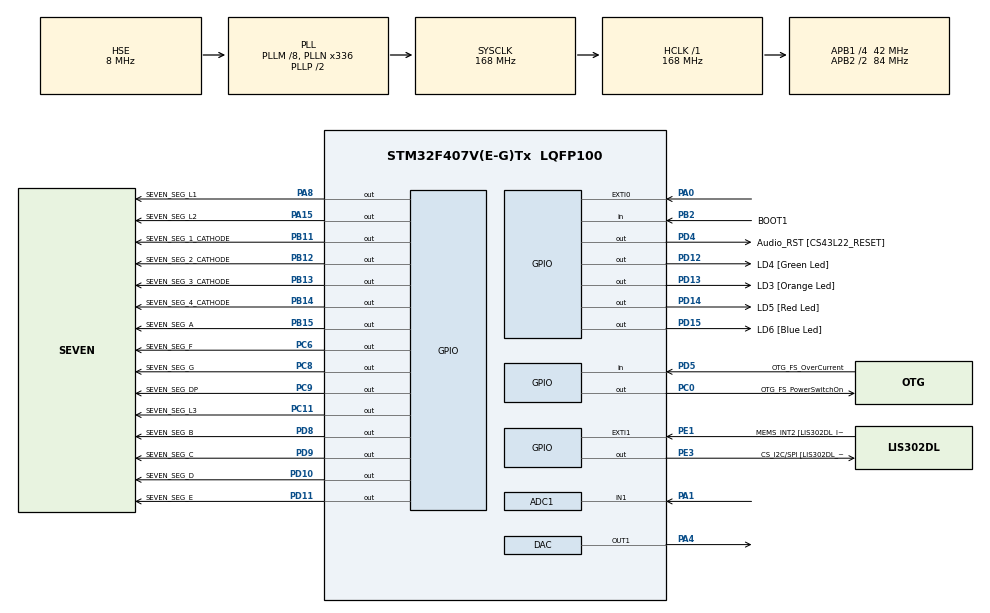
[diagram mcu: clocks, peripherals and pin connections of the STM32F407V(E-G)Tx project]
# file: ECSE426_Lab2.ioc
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ADC1.Channel-0\#ChannelRegularConversion=ADC_CHANNEL_1
ADC1.ClockPrescaler=ADC_CLOCK_SYNC_PCLK_DIV4
ADC1.ContinuousConvMode=DISABLE
ADC1.DMAContinuousRequests=DISABLE
ADC1.DataAlign=ADC_DATAALIGN_RIGHT
ADC1.DiscontinuousConvMode=DISABLE
ADC1.EOCSelection=ADC_EOC_SINGLE_CONV
ADC1.EnableAnalogWatchDog=false
ADC1.ExternalTrigConv=ADC_SOFTWARE_START
ADC1.ExternalTrigConvEdge=ADC_EXTERNALTRIGCONVEDGE_NONE
ADC1.InjNumberOfConversion=0
ADC1.NbrOfConversion=1
ADC1.NbrOfConversionFlag=1
ADC1.Rank-0\#ChannelRegularConversion=1
ADC1.Resolution=ADC_RESOLUTION_10B
ADC1.SamplingTime-0\#ChannelRegularConversion=ADC_SAMPLETIME_3CYCLES
ADC1.ScanConvMode=DISABLE
ADC1.master=1
Mcu.Family=STM32F4
Mcu.Name=STM32F407V(E-G)Tx
Mcu.Package=LQFP100
NVIC.ADC_IRQn=true\:0\:0\:false\:true\:true\:1\:true
NVIC.PriorityGroup=NVIC_PRIORITYGROUP_0
PA0-WKUP.Signal=GPXTI0
PA1.Signal=ADCx_IN1
PA10.GPIO_Label=OTG_FS_ID
PA10.GPIO_Mode=GPIO_MODE_AF_PP
PA10.GPIO_PuPd=GPIO_NOPULL
PA10.GPIO_Speed=GPIO_SPEED_FREQ_LOW
PA10.Signal=USB_OTG_FS_ID
PA11.GPIO_Label=OTG_FS_DM
PA11.GPIO_Mode=GPIO_MODE_AF_PP
PA11.GPIO_PuPd=GPIO_NOPULL
PA11.GPIO_Speed=GPIO_SPEED_FREQ_LOW
PA11.Signal=USB_OTG_FS_DM
PA12.GPIO_Label=OTG_FS_DP
PA12.GPIO_Mode=GPIO_MODE_AF_PP
PA12.GPIO_PuPd=GPIO_NOPULL
PA12.GPIO_Speed=GPIO_SPEED_FREQ_LOW
PA12.Signal=USB_OTG_FS_DP
PA13.GPIO_Label=SWDIO
PA13.Mode=Serial_Wire
PA13.Signal=SYS_JTMS-SWDIO
PA14.GPIO_Label=SWCLK
PA14.Mode=Serial_Wire
PA14.Signal=SYS_JTCK-SWCLK
PA15.GPIO_Label=SEVEN_SEG_L2
PA15.Signal=GPIO_Output
PA4.Signal=COMP_DAC1_group
PA5.GPIO_Label=SPI1_SCK [LIS302DL_SCL/SPC]
PA5.GPIO_Mode=GPIO_MODE_AF_PP
PA5.GPIO_PuPd=GPIO_NOPULL
PA5.GPIO_Speed=GPIO_SPEED_FREQ_LOW
PA5.Signal=SPI1_SCK
PA6.GPIO_Label=SPI1_MISO [LIS302DL_SDO]
PA6.GPIO_Mode=GPIO_MODE_AF_PP
PA6.GPIO_PuPd=GPIO_NOPULL
PA6.GPIO_Speed=GPIO_SPEED_FREQ_LOW
PA6.Signal=SPI1_MISO
PA7.GPIO_Label=SPI1_MOSI [LIS302DL_SDA/SDI/SDO]
PA7.GPIO_Mode=GPIO_MODE_AF_PP
PA7.GPIO_PuPd=GPIO_NOPULL
PA7.GPIO_Speed=GPIO_SPEED_FREQ_LOW
PA7.Signal=SPI1_MOSI
PA8.GPIO_Label=SEVEN_SEG_L1
PA8.Signal=GPIO_Output
PA9.GPIO_Label=VBUS_FS
PA9.GPIO_Mode=GPIO_MODE_INPUT
PA9.GPIO_PuPd=GPIO_NOPULL
PA9.Signal=USB_OTG_FS_VBUS
PB10.GPIO_Label=CLK_IN [MP45DT02_CLK]
PB10.GPIO_Mode=GPIO_MODE_AF_PP
PB10.GPIO_PuPd=GPIO_NOPULL
PB10.GPIO_Speed=GPIO_SPEED_FREQ_LOW
PB10.Signal=I2S2_CK
PB11.GPIO_Label=SEVEN_SEG_1_CATHODE 
PB11.Signal=GPIO_Output
PB12.GPIO_Label=SEVEN_SEG_2_CATHODE
PB12.Signal=GPIO_Output
PB13.GPIO_Label=SEVEN_SEG_3_CATHODE
PB13.Signal=GPIO_Output
PB14.GPIO_Label=SEVEN_SEG_4_CATHODE
PB14.Signal=GPIO_Output
PB15.GPIO_Label=SEVEN_SEG_A
PB15.Signal=GPIO_Output
PB2.GPIO_Label=BOOT1
PB2.GPIO_Mode=GPIO_MODE_INPUT
PB2.GPIO_PuPd=GPIO_NOPULL
PB2.Signal=GPIO_Input
PB3.GPIO_Label=SWO
PB3.Signal=SYS_JTDO-SWO
PB6.GPIO_Label=Audio_SCL [CS43L22_SCL]
PB6.GPIO_Mode=GPIO_MODE_AF_OD
PB6.GPIO_PuPd=GPIO_NOPULL
PB6.GPIO_Speed=GPIO_SPEED_FREQ_LOW
PB6.Signal=I2C1_SCL
PB9.GPIO_Label=Audio_SDA [CS43L22_SDA]
PB9.GPIO_Mode=GPIO_MODE_AF_OD
PB9.GPIO_PuPd=GPIO_NOPULL
PB9.GPIO_Speed=GPIO_SPEED_FREQ_LOW
PB9.Signal=I2C1_SDA
PC0.GPIO_Label=OTG_FS_PowerSwitchOn
PC0.GPIO_PuPd=GPIO_NOPULL
PC0.GPIO_Speed=GPIO_SPEED_FREQ_LOW
PC0.PinState=GPIO_PIN_SET
PC0.Signal=GPIO_Output
PC10.GPIO_Label=I2S3_SCK [CS43L22_SCLK]
PC10.GPIO_Mode=GPIO_MODE_AF_PP
PC10.GPIO_PuPd=GPIO_NOPULL
PC10.GPIO_Speed=GPIO_SPEED_FREQ_LOW
PC10.Signal=I2S3_CK
PC11.GPIO_Label=SEVEN_SEG_L3
PC11.Signal=GPIO_Output
PC12.GPIO_Label=I2S3_SD [CS43L22_SDIN]
PC12.GPIO_Mode=GPIO_MODE_AF_PP
PC12.GPIO_PuPd=GPIO_NOPULL
PC12.GPIO_Speed=GPIO_SPEED_FREQ_LOW
PC12.Signal=I2S3_SD
PC14-OSC32_IN.GPIO_Label=PC14-OSC32_IN
PC14-OSC32_IN.Signal=RCC_OSC32_IN
PC15-OSC32_OUT.GPIO_Label=PC15-OSC32_OUT
PC15-OSC32_OUT.Signal=RCC_OSC32_OUT
PC3.GPIO_Label=PDM_OUT [MP45DT02_DOUT]
PC3.GPIO_Mode=GPIO_MODE_AF_PP
PC3.GPIO_PuPd=GPIO_NOPULL
PC3.GPIO_Speed=GPIO_SPEED_FREQ_LOW
PC3.Signal=I2S2_SD
PC6.GPIO_Label=SEVEN_SEG_F
PC6.Signal=GPIO_Output
PC7.GPIO_Label=I2S3_MCK [CS43L22_MCLK]
PC7.GPIO_Mode=GPIO_MODE_AF_PP
PC7.GPIO_PuPd=GPIO_NOPULL
PC7.GPIO_Speed=GPIO_SPEED_FREQ_LOW
PC7.Signal=I2S3_MCK
PC8.GPIO_Label=SEVEN_SEG_G
PC8.Signal=GPIO_Output
PC9.GPIO_Label=SEVEN_SEG_DP
PC9.Signal=GPIO_Output
PD10.GPIO_Label=SEVEN_SEG_D
PD10.Signal=GPIO_Output
PD11.GPIO_Label=SEVEN_SEG_E
PD11.Signal=GPIO_Output
PD12.GPIO_Label=LD4 [Green Led]
PD12.GPIO_PuPd=GPIO_NOPULL
PD12.GPIO_Speed=GPIO_SPEED_FREQ_LOW
PD12.Signal=GPIO_Output
PD13.GPIO_Label=LD3 [Orange Led]
PD13.GPIO_PuPd=GPIO_NOPULL
PD13.GPIO_Speed=GPIO_SPEED_FREQ_LOW
PD13.Signal=GPIO_Output
PD14.GPIO_Label=LD5 [Red Led]
PD14.GPIO_PuPd=GPIO_NOPULL
PD14.GPIO_Speed=GPIO_SPEED_FREQ_LOW
PD14.Signal=GPIO_Output
PD15.GPIO_Label=LD6 [Blue Led]
PD15.GPIO_PuPd=GPIO_NOPULL
PD15.GPIO_Speed=GPIO_SPEED_FREQ_LOW
PD15.Signal=GPIO_Output
PD4.GPIO_Label=Audio_RST [CS43L22_RESET]
PD4.GPIO_PuPd=GPIO_NOPULL
PD4.GPIO_Speed=GPIO_SPEED_FREQ_LOW
PD4.Signal=GPIO_Output
PD5.GPIO_Label=OTG_FS_OverCurrent
PD5.GPIO_Mode=GPIO_MODE_INPUT
PD5.GPIO_PuPd=GPIO_NOPULL
PD5.Signal=GPIO_Input
PD8.GPIO_Label=SEVEN_SEG_B
PD8.Signal=GPIO_Output
PD9.GPIO_Label=SEVEN_SEG_C
PD9.Signal=GPIO_Output
PE1.GPIO_Label=MEMS_INT2 [LIS302DL_INT2]
PE1.GPIO_ModeDefaultEXTI=GPIO_MODE_EVT_RISING
PE1.GPIO_PuPd=GPIO_NOPULL
PE1.Signal=GPXTI1
PE3.GPIO_Label=CS_I2C/SPI [LIS302DL_CS_I2C/SPI]
PE3.GPIO_PuPd=GPIO_NOPULL
PE3.GPIO_Speed=GPIO_SPEED_FREQ_LOW
PE3.Signal=GPIO_Output
PH0-OSC_IN.GPIO_Label=PH0-OSC_IN
PH0-OSC_IN.Mode=HSE-External-Oscillator
PH0-OSC_IN.Signal=RCC_OSC_IN
PH1-OSC_OUT.GPIO_Label=PH1-OSC_OUT
PH1-OSC_OUT.Mode=HSE-External-Oscillator
PH1-OSC_OUT.Signal=RCC_OSC_OUT
ProjectManager.HeapSize=0x200
ProjectManager.StackSize=0x400
ProjectManager.TargetToolchain=MDK-ARM V5
RCC.48MHZClocksFreq_Value=48000000
RCC.AHBFreq_Value=168000000
RCC.APB1CLKDivider=RCC_HCLK_DIV4
RCC.APB1Freq_Value=42000000
RCC.APB1TimFreq_Value=84000000
RCC.APB2CLKDivider=RCC_HCLK_DIV2
RCC.APB2Freq_Value=84000000
RCC.APB2TimFreq_Value=168000000
RCC.CortexFreq_Value=168000000
RCC.HCLKFreq_Value=168000000
RCC.HSE_VALUE=8000000
RCC.HSI_VALUE=16000000
RCC.LSE_VALUE=32768
RCC.PLLM=8
RCC.PLLN=336
RCC.PLLQ=7
RCC.PLLSourceVirtual=RCC_PLLSOURCE_HSE
RCC.SYSCLKFreq_VALUE=168000000
RCC.SYSCLKSource=RCC_SYSCLKSOURCE_PLLCLK
RCC.VCOOutputFreq_Value=336000000
SH.ADCx_IN1.0=ADC1_IN1,IN1
SH.COMP_DAC1_group.0=DAC_OUT1,DAC_OUT1
board=STM32F4DISCOVERY

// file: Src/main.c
/**
  ******************************************************************************
  * @file           : main.c
  * @brief          : Main program body
  ******************************************************************************
  ** This notice applies to any and all portions of this file
  * that are not between comment pairs USER CODE BEGIN and
  * USER CODE END. Other portions of this file, whether
  * inserted by the user or by software development tools
  * are owned by their respective copyright owners.
  *
  * COPYRIGHT(c) 2018 STMicroelectronics
  *
  * Redistribution and use in source and binary forms, with or without modification,
  * are permitted provided that the following conditions are met:
  *   1. Redistributions of source code must retain the above copyright notice,
  *      this list of conditions and the following disclaimer.
  *   2. Redistributions in binary form must reproduce the above copyright notice,
  *      this list of conditions and the following disclaimer in the documentation
  *      and/or other materials provided with the distribution.
  *   3. Neither the name of STMicroelectronics nor the names of its contributors
  *      may be used to endorse or promote products derived from this software
  *      without specific prior written permission.
  *
  * THIS SOFTWARE IS PROVIDED BY THE COPYRIGHT HOLDERS AND CONTRIBUTORS "AS IS"
  * AND ANY EXPRESS OR IMPLIED WARRANTIES, INCLUDING, BUT NOT LIMITED TO, THE
  * IMPLIED WARRANTIES OF MERCHANTABILITY AND FITNESS FOR A PARTICULAR PURPOSE ARE
  * DISCLAIMED. IN NO EVENT SHALL THE COPYRIGHT HOLDER OR CONTRIBUTORS BE LIABLE
  * FOR ANY DIRECT, INDIRECT, INCIDENTAL, SPECIAL, EXEMPLARY, OR CONSEQUENTIAL
  * DAMAGES (INCLUDING, BUT NOT LIMITED TO, PROCUREMENT OF SUBSTITUTE GOODS OR
  * SERVICES; LOSS OF USE, DATA, OR PROFITS; OR BUSINESS INTERRUPTION) HOWEVER
  * CAUSED AND ON ANY THEORY OF LIABILITY, WHETHER IN CONTRACT, STRICT LIABILITY,
  * OR TORT (INCLUDING NEGLIGENCE OR OTHERWISE) ARISING IN ANY WAY OUT OF THE USE
  * OF THIS SOFTWARE, EVEN IF ADVISED OF THE POSSIBILITY OF SUCH DAMAGE.
  *
  ******************************************************************************
  */
#include "main.h"
#include "stm32f4xx_hal.h"
#include "math.h"

ADC_HandleTypeDef hadc1;

DAC_HandleTypeDef hdac;

/* USER CODE BEGIN PV */
/* Private variables ---------------------------------------------------------*/

int input_vector[INPUT_LENGTH] = {0};
float filterOutputVector[INPUT_LENGTH-ORDER] = {0};
int filterOutputLength = INPUT_LENGTH - ORDER;
uint32_t adcConversion;
float filterOutput;
int digits[3] = {0};
float outputVector[3] = {0};
int outputDigits[4] = {0};
int x[5] = {0};

int ledPosition = 0;
int mathCounter = 0;

float rms_value = 0;
float max_value = 0;
float min_value = 0;

volatile int adcTrigger = 0; //triggers the callback conversion
volatile int displaySwitchTrigger = 0; //triggers the switch between LEDs
volatile int displayedValue = 0; //triggers the change between displayed values (RMS, MAX, MIN)
volatile int buttonReadTrigger = 0; //trigger sent from button press

/* USER CODE END PV */

void SystemClock_Config(void);
static void MX_GPIO_Init(void);
static void MX_ADC1_Init(void);
static void MX_DAC_Init(void);
static void MX_NVIC_Init(void);
void HAL_ADC_ConvCpltCallback(ADC_HandleTypeDef* hadc);
void FIR_C(uint32_t input, float *output);
void digitCalc(float* output, int value);
void ledDriver(int ledPos, int number);
void c_math(float input, float outputVector[]);
extern int buttonPressed(void);

/* USER CODE BEGIN PFP */
/* Private function prototypes -----------------------------------------------*/

/* USER CODE END PFP */

int main(void){
  HAL_Init();

  SystemClock_Config();

  MX_GPIO_Init();
  MX_ADC1_Init();
  MX_DAC_Init();
  MX_NVIC_Init();

	HAL_DAC_Start(&hdac, DAC_CHANNEL_1);
	HAL_DAC_SetValue(&hdac, DAC_CHANNEL_1, DAC_ALIGN_12B_R, 000);

  while (1)
  {
		//ADC interrupt every 50 Hz
		if(adcTrigger >= ADC_TIMER){
			adcTrigger = 0;
			HAL_ADC_Start_IT(&hadc1);
		}

		//update LED display at high frequency
		if(displaySwitchTrigger >= LED_POSITION_TIMER){
			displaySwitchTrigger = 0;
			ledPosition++;
			//reset to 0 when ledPosition reaches 4
			ledPosition = ledPosition % 4;
			//at ledPosition x, display outputDigit[x]
			ledDriver(ledPosition, outputDigits[ledPosition]);
		}
	}
}

void SystemClock_Config(void)
{

  RCC_OscInitTypeDef RCC_OscInitStruct;
  RCC_ClkInitTypeDef RCC_ClkInitStruct;

    /**Configure the main internal regulator output voltage
    */
  __HAL_RCC_PWR_CLK_ENABLE();

  __HAL_PWR_VOLTAGESCALING_CONFIG(PWR_REGULATOR_VOLTAGE_SCALE1);

    /**Initializes the CPU, AHB and APB busses clocks
    */
  RCC_OscInitStruct.OscillatorType = RCC_OSCILLATORTYPE_HSE;
  RCC_OscInitStruct.HSEState = RCC_HSE_ON;
  RCC_OscInitStruct.PLL.PLLState = RCC_PLL_ON;
  RCC_OscInitStruct.PLL.PLLSource = RCC_PLLSOURCE_HSE;
  RCC_OscInitStruct.PLL.PLLM = 8;
  RCC_OscInitStruct.PLL.PLLN = 336;
  RCC_OscInitStruct.PLL.PLLP = RCC_PLLP_DIV2;
  RCC_OscInitStruct.PLL.PLLQ = 7;
  if (HAL_RCC_OscConfig(&RCC_OscInitStruct) != HAL_OK)
  {
    _Error_Handler(__FILE__, __LINE__);
  }

    /**Initializes the CPU, AHB and APB busses clocks
    */
  RCC_ClkInitStruct.ClockType = RCC_CLOCKTYPE_HCLK|RCC_CLOCKTYPE_SYSCLK
                              |RCC_CLOCKTYPE_PCLK1|RCC_CLOCKTYPE_PCLK2;
  RCC_ClkInitStruct.SYSCLKSource = RCC_SYSCLKSOURCE_PLLCLK;
  RCC_ClkInitStruct.AHBCLKDivider = RCC_SYSCLK_DIV1;
  RCC_ClkInitStruct.APB1CLKDivider = RCC_HCLK_DIV4;
  RCC_ClkInitStruct.APB2CLKDivider = RCC_HCLK_DIV2;

  if (HAL_RCC_ClockConfig(&RCC_ClkInitStruct, FLASH_LATENCY_5) != HAL_OK)
  {
    _Error_Handler(__FILE__, __LINE__);
  }

    /**Configure the Systick interrupt time
    */
  HAL_SYSTICK_Config(HAL_RCC_GetHCLKFreq()/1000);

    /**Configure the Systick
    */
  HAL_SYSTICK_CLKSourceConfig(SYSTICK_CLKSOURCE_HCLK);

  /* SysTick_IRQn interrupt configuration */
  HAL_NVIC_SetPriority(SysTick_IRQn, 0, 0);
}

/**
  * @brief NVIC Configuration.
  * @retval None
  */
static void MX_NVIC_Init(void)
{
  // ADC_IRQn interrupt configuration
  HAL_NVIC_SetPriority(ADC_IRQn, 0, 0);
  HAL_NVIC_EnableIRQ(ADC_IRQn);
}

/* ADC1 init function */
static void MX_ADC1_Init(void)
{

  ADC_ChannelConfTypeDef sConfig;

    /**Configure the global features of the ADC (Clock, Resolution, Data Alignment and number of conversion)
    */
  hadc1.Instance = ADC1;
  hadc1.Init.ClockPrescaler = ADC_CLOCK_SYNC_PCLK_DIV4;
  hadc1.Init.Resolution = ADC_RESOLUTION_12B;
  hadc1.Init.ScanConvMode = DISABLE;
  hadc1.Init.ContinuousConvMode = DISABLE;
  hadc1.Init.DiscontinuousConvMode = DISABLE;
  hadc1.Init.ExternalTrigConvEdge = ADC_EXTERNALTRIGCONVEDGE_NONE;
  hadc1.Init.ExternalTrigConv = ADC_SOFTWARE_START;
  hadc1.Init.DataAlign = ADC_DATAALIGN_RIGHT;
  hadc1.Init.NbrOfConversion = 1;
  hadc1.Init.DMAContinuousRequests = DISABLE;
  hadc1.Init.EOCSelection = ADC_EOC_SINGLE_CONV;
  if (HAL_ADC_Init(&hadc1) != HAL_OK)
  {
    _Error_Handler(__FILE__, __LINE__);
  }

    /**Configure for the selected ADC regular channel its corresponding rank in the sequencer and its sample time.
    */
  sConfig.Channel = ADC_CHANNEL_1;
  sConfig.Rank = 1;
  sConfig.SamplingTime = ADC_SAMPLETIME_3CYCLES;
  if (HAL_ADC_ConfigChannel(&hadc1, &sConfig) != HAL_OK)
  {
    _Error_Handler(__FILE__, __LINE__);
  }

}

/* DAC init function */
static void MX_DAC_Init(void)
{

  DAC_ChannelConfTypeDef sConfig;

    /**DAC Initialization
    */
  hdac.Instance = DAC;
  if (HAL_DAC_Init(&hdac) != HAL_OK)
  {
    _Error_Handler(__FILE__, __LINE__);
  }

    /**DAC channel OUT1 config
    */
  sConfig.DAC_Trigger = DAC_TRIGGER_NONE;
  sConfig.DAC_OutputBuffer = DAC_OUTPUTBUFFER_ENABLE;
  if (HAL_DAC_ConfigChannel(&hdac, &sConfig, DAC_CHANNEL_1) != HAL_OK)
  {
    _Error_Handler(__FILE__, __LINE__);
  }

}

/** Configure pins as
        * Analog
        * Input
        * Output
        * EVENT_OUT
        * EXTI
     PC3   ------> I2S2_SD
     PA5   ------> SPI1_SCK
     PA6   ------> SPI1_MISO
     PA7   ------> SPI1_MOSI
     PB10   ------> I2S2_CK
     PC7   ------> I2S3_MCK
     PA9   ------> USB_OTG_FS_VBUS
     PA10   ------> USB_OTG_FS_ID
     PA11   ------> USB_OTG_FS_DM
     PA12   ------> USB_OTG_FS_DP
     PC10   ------> I2S3_CK
     PC12   ------> I2S3_SD
     PB6   ------> I2C1_SCL
     PB9   ------> I2C1_SDA
*/
static void MX_GPIO_Init(void)
{

  GPIO_InitTypeDef GPIO_InitStruct;

  /* GPIO Ports Clock Enable */
  __HAL_RCC_GPIOE_CLK_ENABLE();
  __HAL_RCC_GPIOC_CLK_ENABLE();
  __HAL_RCC_GPIOH_CLK_ENABLE();
  __HAL_RCC_GPIOA_CLK_ENABLE();
  __HAL_RCC_GPIOB_CLK_ENABLE();
  __HAL_RCC_GPIOD_CLK_ENABLE();

  /*Configure GPIO pin Output Level */
  HAL_GPIO_WritePin(CS_I2C_SPI_GPIO_Port, CS_I2C_SPI_Pin, GPIO_PIN_RESET);

  /*Configure GPIO pin Output Level */
  HAL_GPIO_WritePin(OTG_FS_PowerSwitchOn_GPIO_Port, OTG_FS_PowerSwitchOn_Pin, GPIO_PIN_SET);

  /*Configure GPIO pin Output Level */
  HAL_GPIO_WritePin(GPIOB, SEVEN_SEG_1_CATHODE_Pin|SEVEN_SEG_2_CATHODE_Pin|SEVEN_SEG_3_CATHODE_Pin|SEVEN_SEG_4_CATHODE_Pin
                          |SEVEN_SEG_A_Pin, GPIO_PIN_RESET);

  /*Configure GPIO pin Output Level */
  HAL_GPIO_WritePin(GPIOD, SEVEN_SEG_B_Pin|SEVEN_SEG_C_Pin|SEVEN_SEG_D_Pin|SEVEN_SEG_E_Pin
                          |LD4_Pin|LD3_Pin|LD5_Pin|LD6_Pin
                          |Audio_RST_Pin, GPIO_PIN_RESET);

  /*Configure GPIO pin Output Level */
  HAL_GPIO_WritePin(GPIOC, SEVEN_SEG_F_Pin|SEVEN_SEG_G_Pin|SEVEN_SEG_DP_Pin|SEVEN_SEG_L3_Pin, GPIO_PIN_RESET);

  /*Configure GPIO pin Output Level */
  HAL_GPIO_WritePin(GPIOA, SEVEN_SEG_L1_Pin|SEVEN_SEG_L2_Pin, GPIO_PIN_RESET);

  /*Configure GPIO pin : CS_I2C_SPI_Pin */
  GPIO_InitStruct.Pin = CS_I2C_SPI_Pin;
  GPIO_InitStruct.Mode = GPIO_MODE_OUTPUT_PP;
  GPIO_InitStruct.Pull = GPIO_NOPULL;
  GPIO_InitStruct.Speed = GPIO_SPEED_FREQ_LOW;
  HAL_GPIO_Init(CS_I2C_SPI_GPIO_Port, &GPIO_InitStruct);

  /*Configure GPIO pins : OTG_FS_PowerSwitchOn_Pin SEVEN_SEG_F_Pin SEVEN_SEG_G_Pin SEVEN_SEG_DP_Pin
                           SEVEN_SEG_L3_Pin */
  GPIO_InitStruct.Pin = OTG_FS_PowerSwitchOn_Pin|SEVEN_SEG_F_Pin|SEVEN_SEG_G_Pin|SEVEN_SEG_DP_Pin
                          |SEVEN_SEG_L3_Pin;
  GPIO_InitStruct.Mode = GPIO_MODE_OUTPUT_PP;
  GPIO_InitStruct.Pull = GPIO_NOPULL;
  GPIO_InitStruct.Speed = GPIO_SPEED_FREQ_LOW;
  HAL_GPIO_Init(GPIOC, &GPIO_InitStruct);

  /*Configure GPIO pin : PDM_OUT_Pin */
  GPIO_InitStruct.Pin = PDM_OUT_Pin;
  GPIO_InitStruct.Mode = GPIO_MODE_AF_PP;
  GPIO_InitStruct.Pull = GPIO_NOPULL;
  GPIO_InitStruct.Speed = GPIO_SPEED_FREQ_LOW;
  GPIO_InitStruct.Alternate = GPIO_AF5_SPI2;
  HAL_GPIO_Init(PDM_OUT_GPIO_Port, &GPIO_InitStruct);

  /*Configure GPIO pin : B1_Pin */
  GPIO_InitStruct.Pin = B1_Pin;
  GPIO_InitStruct.Mode = GPIO_MODE_EVT_RISING;
  GPIO_InitStruct.Pull = GPIO_NOPULL;
  HAL_GPIO_Init(B1_GPIO_Port, &GPIO_InitStruct);

  /*Configure GPIO pins : SPI1_SCK_Pin SPI1_MISO_Pin SPI1_MOSI_Pin */
  GPIO_InitStruct.Pin = SPI1_SCK_Pin|SPI1_MISO_Pin|SPI1_MOSI_Pin;
  GPIO_InitStruct.Mode = GPIO_MODE_AF_PP;
  GPIO_InitStruct.Pull = GPIO_NOPULL;
  GPIO_InitStruct.Speed = GPIO_SPEED_FREQ_LOW;
  GPIO_InitStruct.Alternate = GPIO_AF5_SPI1;
  HAL_GPIO_Init(GPIOA, &GPIO_InitStruct);

  /*Configure GPIO pin : BOOT1_Pin */
  GPIO_InitStruct.Pin = BOOT1_Pin;
  GPIO_InitStruct.Mode = GPIO_MODE_INPUT;
  GPIO_InitStruct.Pull = GPIO_NOPULL;
  HAL_GPIO_Init(BOOT1_GPIO_Port, &GPIO_InitStruct);

  /*Configure GPIO pin : CLK_IN_Pin */
  GPIO_InitStruct.Pin = CLK_IN_Pin;
  GPIO_InitStruct.Mode = GPIO_MODE_AF_PP;
  GPIO_InitStruct.Pull = GPIO_NOPULL;
  GPIO_InitStruct.Speed = GPIO_SPEED_FREQ_LOW;
  GPIO_InitStruct.Alternate = GPIO_AF5_SPI2;
  HAL_GPIO_Init(CLK_IN_GPIO_Port, &GPIO_InitStruct);

  /*Configure GPIO pins : SEVEN_SEG_1_CATHODE_Pin SEVEN_SEG_2_CATHODE_Pin SEVEN_SEG_3_CATHODE_Pin SEVEN_SEG_4_CATHODE_Pin
                           SEVEN_SEG_A_Pin */
  GPIO_InitStruct.Pin = SEVEN_SEG_1_CATHODE_Pin|SEVEN_SEG_2_CATHODE_Pin|SEVEN_SEG_3_CATHODE_Pin|SEVEN_SEG_4_CATHODE_Pin
                          |SEVEN_SEG_A_Pin;
  GPIO_InitStruct.Mode = GPIO_MODE_OUTPUT_PP;
  GPIO_InitStruct.Pull = GPIO_NOPULL;
  GPIO_InitStruct.Speed = GPIO_SPEED_FREQ_LOW;
  HAL_GPIO_Init(GPIOB, &GPIO_InitStruct);

  /*Configure GPIO pins : SEVEN_SEG_B_Pin SEVEN_SEG_C_Pin SEVEN_SEG_D_Pin SEVEN_SEG_E_Pin
                           LD4_Pin LD3_Pin LD5_Pin LD6_Pin
                           Audio_RST_Pin */
  GPIO_InitStruct.Pin = SEVEN_SEG_B_Pin|SEVEN_SEG_C_Pin|SEVEN_SEG_D_Pin|SEVEN_SEG_E_Pin
                          |LD4_Pin|LD3_Pin|LD5_Pin|LD6_Pin
                          |Audio_RST_Pin;
  GPIO_InitStruct.Mode = GPIO_MODE_OUTPUT_PP;
  GPIO_InitStruct.Pull = GPIO_NOPULL;
  GPIO_InitStruct.Speed = GPIO_SPEED_FREQ_LOW;
  HAL_GPIO_Init(GPIOD, &GPIO_InitStruct);

  /*Configure GPIO pins : I2S3_MCK_Pin I2S3_SCK_Pin I2S3_SD_Pin */
  GPIO_InitStruct.Pin = I2S3_MCK_Pin|I2S3_SCK_Pin|I2S3_SD_Pin;
  GPIO_InitStruct.Mode = GPIO_MODE_AF_PP;
  GPIO_InitStruct.Pull = GPIO_NOPULL;
  GPIO_InitStruct.Speed = GPIO_SPEED_FREQ_LOW;
  GPIO_InitStruct.Alternate = GPIO_AF6_SPI3;
  HAL_GPIO_Init(GPIOC, &GPIO_InitStruct);

  /*Configure GPIO pins : SEVEN_SEG_L1_Pin SEVEN_SEG_L2_Pin */
  GPIO_InitStruct.Pin = SEVEN_SEG_L1_Pin|SEVEN_SEG_L2_Pin;
  GPIO_InitStruct.Mode = GPIO_MODE_OUTPUT_PP;
  GPIO_InitStruct.Pull = GPIO_NOPULL;
  GPIO_InitStruct.Speed = GPIO_SPEED_FREQ_LOW;
  HAL_GPIO_Init(GPIOA, &GPIO_InitStruct);

  /*Configure GPIO pin : VBUS_FS_Pin */
  GPIO_InitStruct.Pin = VBUS_FS_Pin;
  GPIO_InitStruct.Mode = GPIO_MODE_INPUT;
  GPIO_InitStruct.Pull = GPIO_NOPULL;
  HAL_GPIO_Init(VBUS_FS_GPIO_Port, &GPIO_InitStruct);

  /*Configure GPIO pins : OTG_FS_ID_Pin OTG_FS_DM_Pin OTG_FS_DP_Pin */
  GPIO_InitStruct.Pin = OTG_FS_ID_Pin|OTG_FS_DM_Pin|OTG_FS_DP_Pin;
  GPIO_InitStruct.Mode = GPIO_MODE_AF_PP;
  GPIO_InitStruct.Pull = GPIO_NOPULL;
  GPIO_InitStruct.Speed = GPIO_SPEED_FREQ_LOW;
  GPIO_InitStruct.Alternate = GPIO_AF10_OTG_FS;
  HAL_GPIO_Init(GPIOA, &GPIO_InitStruct);

  /*Configure GPIO pin : OTG_FS_OverCurrent_Pin */
  GPIO_InitStruct.Pin = OTG_FS_OverCurrent_Pin;
  GPIO_InitStruct.Mode = GPIO_MODE_INPUT;
  GPIO_InitStruct.Pull = GPIO_NOPULL;
  HAL_GPIO_Init(OTG_FS_OverCurrent_GPIO_Port, &GPIO_InitStruct);

  /*Configure GPIO pins : Audio_SCL_Pin Audio_SDA_Pin */
  GPIO_InitStruct.Pin = Audio_SCL_Pin|Audio_SDA_Pin;
  GPIO_InitStruct.Mode = GPIO_MODE_AF_OD;
  GPIO_InitStruct.Pull = GPIO_PULLUP;
  GPIO_InitStruct.Speed = GPIO_SPEED_FREQ_LOW;
  GPIO_InitStruct.Alternate = GPIO_AF4_I2C1;
  HAL_GPIO_Init(GPIOB, &GPIO_InitStruct);

  /*Configure GPIO pin : MEMS_INT2_Pin */
  GPIO_InitStruct.Pin = MEMS_INT2_Pin;
  GPIO_InitStruct.Mode = GPIO_MODE_EVT_RISING;
  GPIO_InitStruct.Pull = GPIO_NOPULL;
  HAL_GPIO_Init(MEMS_INT2_GPIO_Port, &GPIO_InitStruct);

	/* EXTI interrupt init*/
	HAL_NVIC_SetPriority(EXTI0_IRQn, 0, 0);
	HAL_NVIC_EnableIRQ(EXTI0_IRQn);
}

/* USER CODE BEGIN 4 */
void HAL_ADC_ConvCpltCallback(ADC_HandleTypeDef* hadc){

		//get converted ADC value
		adcConversion = HAL_ADC_GetValue(hadc);

		//send to filter
		FIR_C(adcConversion, &filterOutput);

		filterOutput = filterOutput * 3.0 / 4096.0; //12bit conversion, Vref at 3V

		c_math(filterOutput, outputVector);

		digitCalc(outputVector, displayedValue); //value indicator in outputDigit[0], tens in outputDigit[1], tenths in outputDigit[2], hundredths in outputDigit[3]

		HAL_ADC_Stop_IT(&hadc1); //disable the ADC interrupt
}

void FIR_C(uint32_t input, float *output) {

	float coefficients[5] = {0.2,0.2,0.2,0.2,0.2};
	//moving window
	for(int i = 0; i < 4; i++){
		x[i] = x[i+1];
	}
	//set new input to final value in window
	x[4] = input;
	float returnedOutput = 0;
	//sum of products of coefficient and input
	for(int i = 0; i < 5; i++){
		returnedOutput += x[i] * coefficients[4-i];
	}
	*output = returnedOutput;
		//printf("The input of the filter is: %d \n", input);
		//printf("The output of the filter is: %f \n", *output);
}

void c_math(float input, float outputVector[]){

	printf("The input is: %f \n", input);
	//set comparing variable to input only on first math loop
	if(mathCounter == 0){
		min_value = input;
		max_value = input;
		rms_value = input*input;
	}
	//compare values to previously set min/max values if not on first math loop
	else {
		if(input < min_value){
			min_value = input;
		}
		else if(input > max_value){
			max_value = input;
		}
		rms_value = rms_value + (input*input);
	}
	mathCounter++;
	//update stored values every 10 seconds
	if(mathCounter >= 500){
		mathCounter = 0;
	}
	//rms is square root of (sum of squares divided by length)
	outputVector[0] = (float) (sqrt(rms_value/((float)(mathCounter))));
	outputVector[1] = max_value;
	outputVector[2] = min_value;
}

void digitCalc(float* outputVector, int value){ 	//where outputVector is {rms, max, min}

	int firstDigit, secondDigit, thirdDigit = 0;

	float temp = outputVector[value];

	//parse first, second and third digits in calculated value
	firstDigit = (int) (temp);
	secondDigit = (int) ((temp - (float)(firstDigit)) * 10.0f);
	thirdDigit = (int) ((((temp - (float)(firstDigit)) * 10.0f) - (float)(secondDigit)) * 10.0f);

	//set digits to output variables
	outputDigits[0] = value;
	outputDigits[1] = firstDigit;
	outputDigits[2] = secondDigit;
	outputDigits[3] = thirdDigit;
}

void ledDriver(int ledPos, int number){
	if(number == 0){
			HAL_GPIO_WritePin(GPIOB, SEVEN_SEG_A_Pin, GPIO_PIN_SET);
			HAL_GPIO_WritePin(GPIOD, SEVEN_SEG_B_Pin, GPIO_PIN_SET);
			HAL_GPIO_WritePin(GPIOD, SEVEN_SEG_C_Pin, GPIO_PIN_SET);
			HAL_GPIO_WritePin(GPIOD, SEVEN_SEG_D_Pin, GPIO_PIN_SET);
			HAL_GPIO_WritePin(GPIOD, SEVEN_SEG_E_Pin, GPIO_PIN_SET);
			HAL_GPIO_WritePin(GPIOC, SEVEN_SEG_F_Pin, GPIO_PIN_SET);
			HAL_GPIO_WritePin(GPIOC, SEVEN_SEG_G_Pin, GPIO_PIN_RESET);
	}
	else if(number == 1){
			HAL_GPIO_WritePin(GPIOB, SEVEN_SEG_A_Pin, GPIO_PIN_RESET);
			HAL_GPIO_WritePin(GPIOD, SEVEN_SEG_B_Pin, GPIO_PIN_SET);
			HAL_GPIO_WritePin(GPIOD, SEVEN_SEG_C_Pin, GPIO_PIN_SET);
			HAL_GPIO_WritePin(GPIOD, SEVEN_SEG_D_Pin, GPIO_PIN_RESET);
			HAL_GPIO_WritePin(GPIOD, SEVEN_SEG_E_Pin, GPIO_PIN_RESET);
			HAL_GPIO_WritePin(GPIOC, SEVEN_SEG_F_Pin, GPIO_PIN_RESET);
			HAL_GPIO_WritePin(GPIOC, SEVEN_SEG_G_Pin, GPIO_PIN_RESET);
	}
	else if(number == 2){
			HAL_GPIO_WritePin(GPIOB, SEVEN_SEG_A_Pin, GPIO_PIN_SET);
			HAL_GPIO_WritePin(GPIOD, SEVEN_SEG_B_Pin, GPIO_PIN_SET);
			HAL_GPIO_WritePin(GPIOD, SEVEN_SEG_C_Pin, GPIO_PIN_RESET);
			HAL_GPIO_WritePin(GPIOD, SEVEN_SEG_D_Pin, GPIO_PIN_SET);
			HAL_GPIO_WritePin(GPIOD, SEVEN_SEG_E_Pin, GPIO_PIN_SET);
			HAL_GPIO_WritePin(GPIOC, SEVEN_SEG_F_Pin, GPIO_PIN_RESET);
			HAL_GPIO_WritePin(GPIOC, SEVEN_SEG_G_Pin, GPIO_PIN_SET);
	}
	else if(number == 3){
			HAL_GPIO_WritePin(GPIOB, SEVEN_SEG_A_Pin, GPIO_PIN_SET);
			HAL_GPIO_WritePin(GPIOD, SEVEN_SEG_B_Pin, GPIO_PIN_SET);
			HAL_GPIO_WritePin(GPIOD, SEVEN_SEG_C_Pin, GPIO_PIN_SET);
			HAL_GPIO_WritePin(GPIOD, SEVEN_SEG_D_Pin, GPIO_PIN_SET);
			HAL_GPIO_WritePin(GPIOD, SEVEN_SEG_E_Pin, GPIO_PIN_RESET);
			HAL_GPIO_WritePin(GPIOC, SEVEN_SEG_F_Pin, GPIO_PIN_RESET);
			HAL_GPIO_WritePin(GPIOC, SEVEN_SEG_G_Pin, GPIO_PIN_SET);
	}
	else if(number == 4){
			HAL_GPIO_WritePin(GPIOB, SEVEN_SEG_A_Pin, GPIO_PIN_RESET);
			HAL_GPIO_WritePin(GPIOD, SEVEN_SEG_B_Pin, GPIO_PIN_SET);
			HAL_GPIO_WritePin(GPIOD, SEVEN_SEG_C_Pin, GPIO_PIN_SET);
			HAL_GPIO_WritePin(GPIOD, SEVEN_SEG_D_Pin, GPIO_PIN_RESET);
			HAL_GPIO_WritePin(GPIOD, SEVEN_SEG_E_Pin, GPIO_PIN_RESET);
			HAL_GPIO_WritePin(GPIOC, SEVEN_SEG_F_Pin, GPIO_PIN_SET);
			HAL_GPIO_WritePin(GPIOC, SEVEN_SEG_G_Pin, GPIO_PIN_SET);
	}
	else if(number == 5){
			HAL_GPIO_WritePin(GPIOB, SEVEN_SEG_A_Pin, GPIO_PIN_SET);
			HAL_GPIO_WritePin(GPIOD, SEVEN_SEG_B_Pin, GPIO_PIN_RESET);
			HAL_GPIO_WritePin(GPIOD, SEVEN_SEG_C_Pin, GPIO_PIN_SET);
			HAL_GPIO_WritePin(GPIOD, SEVEN_SEG_D_Pin, GPIO_PIN_SET);
			HAL_GPIO_WritePin(GPIOD, SEVEN_SEG_E_Pin, GPIO_PIN_RESET);
			HAL_GPIO_WritePin(GPIOC, SEVEN_SEG_F_Pin, GPIO_PIN_SET);
			HAL_GPIO_WritePin(GPIOC, SEVEN_SEG_G_Pin, GPIO_PIN_SET);
	}
	else if(number == 6){
			HAL_GPIO_WritePin(GPIOB, SEVEN_SEG_A_Pin, GPIO_PIN_SET);
			HAL_GPIO_WritePin(GPIOD, SEVEN_SEG_B_Pin, GPIO_PIN_RESET);
			HAL_GPIO_WritePin(GPIOD, SEVEN_SEG_C_Pin, GPIO_PIN_SET);
			HAL_GPIO_WritePin(GPIOD, SEVEN_SEG_D_Pin, GPIO_PIN_SET);
			HAL_GPIO_WritePin(GPIOD, SEVEN_SEG_E_Pin, GPIO_PIN_SET);
			HAL_GPIO_WritePin(GPIOC, SEVEN_SEG_F_Pin, GPIO_PIN_SET);
			HAL_GPIO_WritePin(GPIOC, SEVEN_SEG_G_Pin, GPIO_PIN_SET);
	}
	else if(number == 7){
			HAL_GPIO_WritePin(GPIOB, SEVEN_SEG_A_Pin, GPIO_PIN_SET);
			HAL_GPIO_WritePin(GPIOD, SEVEN_SEG_B_Pin, GPIO_PIN_SET);
			HAL_GPIO_WritePin(GPIOD, SEVEN_SEG_C_Pin, GPIO_PIN_SET);
			HAL_GPIO_WritePin(GPIOD, SEVEN_SEG_D_Pin, GPIO_PIN_RESET);
			HAL_GPIO_WritePin(GPIOD, SEVEN_SEG_E_Pin, GPIO_PIN_RESET);
			HAL_GPIO_WritePin(GPIOC, SEVEN_SEG_F_Pin, GPIO_PIN_RESET);
			HAL_GPIO_WritePin(GPIOC, SEVEN_SEG_G_Pin, GPIO_PIN_RESET);
		}
	else if(number == 8){
			HAL_GPIO_WritePin(GPIOB, SEVEN_SEG_A_Pin, GPIO_PIN_SET);
			HAL_GPIO_WritePin(GPIOD, SEVEN_SEG_B_Pin, GPIO_PIN_SET);
			HAL_GPIO_WritePin(GPIOD, SEVEN_SEG_C_Pin, GPIO_PIN_SET);
			HAL_GPIO_WritePin(GPIOD, SEVEN_SEG_D_Pin, GPIO_PIN_SET);
			HAL_GPIO_WritePin(GPIOD, SEVEN_SEG_E_Pin, GPIO_PIN_SET);
			HAL_GPIO_WritePin(GPIOC, SEVEN_SEG_F_Pin, GPIO_PIN_SET);
			HAL_GPIO_WritePin(GPIOC, SEVEN_SEG_G_Pin, GPIO_PIN_SET);
		}
	else if(number == 9){
			HAL_GPIO_WritePin(GPIOB, SEVEN_SEG_A_Pin, GPIO_PIN_SET);
			HAL_GPIO_WritePin(GPIOD, SEVEN_SEG_B_Pin, GPIO_PIN_SET);
			HAL_GPIO_WritePin(GPIOD, SEVEN_SEG_C_Pin, GPIO_PIN_SET);
			HAL_GPIO_WritePin(GPIOD, SEVEN_SEG_D_Pin, GPIO_PIN_SET);
			HAL_GPIO_WritePin(GPIOD, SEVEN_SEG_E_Pin, GPIO_PIN_RESET);
			HAL_GPIO_WritePin(GPIOC, SEVEN_SEG_F_Pin, GPIO_PIN_SET);
			HAL_GPIO_WritePin(GPIOC, SEVEN_SEG_G_Pin, GPIO_PIN_SET);
		}
		if(ledPos == 0){
			HAL_GPIO_WritePin(GPIOB, SEVEN_SEG_1_CATHODE_Pin, GPIO_PIN_SET);
			HAL_GPIO_WritePin(GPIOB, SEVEN_SEG_2_CATHODE_Pin, GPIO_PIN_RESET);
			HAL_GPIO_WritePin(GPIOB, SEVEN_SEG_3_CATHODE_Pin, GPIO_PIN_RESET);
			HAL_GPIO_WritePin(GPIOB, SEVEN_SEG_4_CATHODE_Pin, GPIO_PIN_RESET);
		}
	else if(ledPos == 1){ //position (X)XX
			HAL_GPIO_WritePin(GPIOB, SEVEN_SEG_1_CATHODE_Pin, GPIO_PIN_RESET);
			HAL_GPIO_WritePin(GPIOB, SEVEN_SEG_2_CATHODE_Pin, GPIO_PIN_SET);
			HAL_GPIO_WritePin(GPIOB, SEVEN_SEG_3_CATHODE_Pin, GPIO_PIN_RESET);
			HAL_GPIO_WritePin(GPIOB, SEVEN_SEG_4_CATHODE_Pin, GPIO_PIN_RESET);
		}
	else if(ledPos == 2){		//position X(X)X
			HAL_GPIO_WritePin(GPIOB, SEVEN_SEG_1_CATHODE_Pin, GPIO_PIN_RESET);
			HAL_GPIO_WritePin(GPIOB, SEVEN_SEG_2_CATHODE_Pin, GPIO_PIN_RESET);
			HAL_GPIO_WritePin(GPIOB, SEVEN_SEG_3_CATHODE_Pin, GPIO_PIN_SET);
			HAL_GPIO_WritePin(GPIOB, SEVEN_SEG_4_CATHODE_Pin, GPIO_PIN_RESET);
		}
	else if(ledPos == 3){//position XX(X)
			HAL_GPIO_WritePin(GPIOB, SEVEN_SEG_1_CATHODE_Pin, GPIO_PIN_RESET);
			HAL_GPIO_WritePin(GPIOB, SEVEN_SEG_2_CATHODE_Pin, GPIO_PIN_RESET);
			HAL_GPIO_WritePin(GPIOB, SEVEN_SEG_3_CATHODE_Pin, GPIO_PIN_RESET);
			HAL_GPIO_WritePin(GPIOB, SEVEN_SEG_4_CATHODE_Pin, GPIO_PIN_SET);
		}
}

int buttonPressed(){
	if(HAL_GPIO_ReadPin(GPIOA, GPIO_PIN_0)){
		return 1;
	}
	else{
		return 0;
	}
}
/* USER CODE END 4 */

void _Error_Handler(char *file, int line)
{
  while(1)
  {
  }
}

/************************ (C) COPYRIGHT STMicroelectronics *****END OF FILE****/
